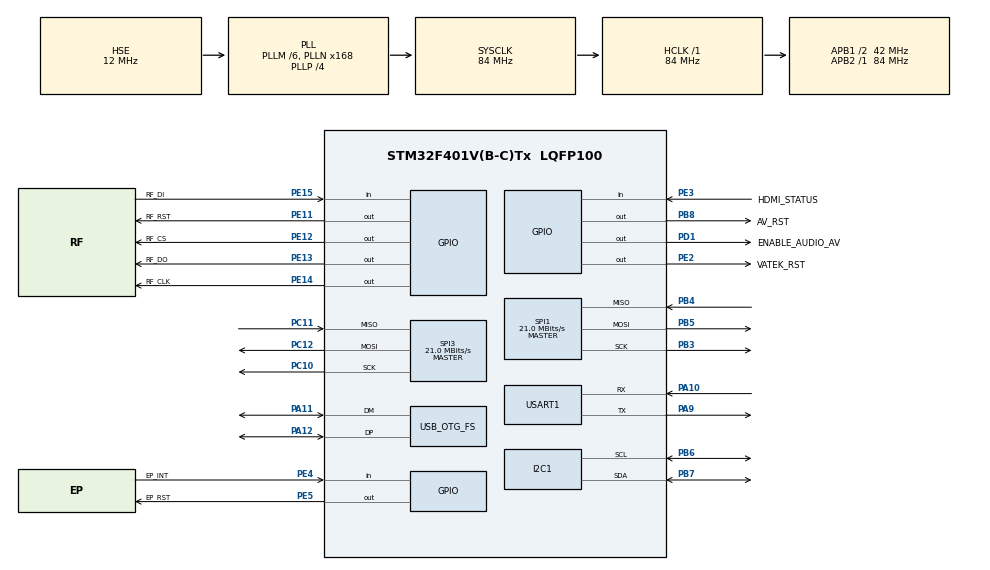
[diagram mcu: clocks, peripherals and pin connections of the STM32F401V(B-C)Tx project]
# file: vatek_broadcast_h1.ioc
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I2C1.I2C_Mode=I2C_Fast
Mcu.Family=STM32F4
Mcu.Name=STM32F401V(B-C)Tx
Mcu.Package=LQFP100
NVIC.OTG_FS_IRQn=true\:0\:0\:false\:false\:true\:false\:true
NVIC.PriorityGroup=NVIC_PRIORITYGROUP_4
NVIC.USART1_IRQn=true\:0\:0\:false\:false\:true\:true\:true
PA10.Mode=Asynchronous
PA10.Signal=USART1_RX
PA11.Mode=Device_Only
PA11.Signal=USB_OTG_FS_DM
PA12.Mode=Device_Only
PA12.Signal=USB_OTG_FS_DP
PA13.Mode=Serial_Wire
PA13.Signal=SYS_JTMS-SWDIO
PA14.Mode=Serial_Wire
PA14.Signal=SYS_JTCK-SWCLK
PA9.Mode=Asynchronous
PA9.Signal=USART1_TX
PB3.Mode=Full_Duplex_Master
PB3.Signal=SPI1_SCK
PB4.Mode=Full_Duplex_Master
PB4.Signal=SPI1_MISO
PB5.Mode=Full_Duplex_Master
PB5.Signal=SPI1_MOSI
PB6.Mode=I2C
PB6.Signal=I2C1_SCL
PB7.Mode=I2C
PB7.Signal=I2C1_SDA
PB8.GPIO_Label=AV_RST
PB8.Signal=GPIO_Output
PC10.Mode=Full_Duplex_Master
PC10.Signal=SPI3_SCK
PC11.Mode=Full_Duplex_Master
PC11.Signal=SPI3_MISO
PC12.Mode=Full_Duplex_Master
PC12.Signal=SPI3_MOSI
PC14-OSC32_IN.Mode=LSE-External-Oscillator
PC14-OSC32_IN.Signal=RCC_OSC32_IN
PC15-OSC32_OUT.Mode=LSE-External-Oscillator
PC15-OSC32_OUT.Signal=RCC_OSC32_OUT
PD1.GPIO_Label=ENABLE_AUDIO_AV
PD1.Signal=GPIO_Output
PE11.GPIO_Label=RF_RST
PE11.Signal=GPIO_Output
PE12.GPIO_Label=RF_CS
PE12.Signal=GPIO_Output
PE13.GPIO_Label=RF_DO
PE13.Signal=GPIO_Output
PE14.GPIO_Label=RF_CLK
PE14.Signal=GPIO_Output
PE15.GPIO_Label=RF_DI
PE15.Signal=GPIO_Input
PE2.GPIO_Label=VATEK_RST
PE2.Signal=GPIO_Output
PE3.GPIO_Label=HDMI_STATUS
PE3.Signal=GPIO_Input
PE4.GPIO_Label=EP_INT
PE4.Signal=GPIO_Input
PE5.GPIO_Label=EP_RST
PE5.Signal=GPIO_Output
PH0\ -\ OSC_IN.Mode=HSE-External-Oscillator
PH0\ -\ OSC_IN.Signal=RCC_OSC_IN
PH1\ -\ OSC_OUT.Mode=HSE-External-Oscillator
PH1\ -\ OSC_OUT.Signal=RCC_OSC_OUT
ProjectManager.HeapSize=0x4000
ProjectManager.StackSize=0x800
ProjectManager.TargetToolchain=MDK-ARM V5.27
RCC.48MHZClocksFreq_Value=48000000
RCC.AHBFreq_Value=84000000
RCC.APB1CLKDivider=RCC_HCLK_DIV2
RCC.APB1Freq_Value=42000000
RCC.APB1TimFreq_Value=84000000
RCC.APB2Freq_Value=84000000
RCC.APB2TimFreq_Value=84000000
RCC.CortexFreq_Value=84000000
RCC.HCLKFreq_Value=84000000
RCC.HSE_VALUE=12000000
RCC.HSI_VALUE=16000000
RCC.PLLM=6
RCC.PLLN=168
RCC.PLLP=RCC_PLLP_DIV4
RCC.PLLQ=7
RCC.SYSCLKFreq_VALUE=84000000
RCC.SYSCLKSource=RCC_SYSCLKSOURCE_PLLCLK
RCC.VCOOutputFreq_Value=336000000
SPI1.BaudRatePrescaler=SPI_BAUDRATEPRESCALER_4
SPI1.CalculateBaudRate=21.0 MBits/s
SPI1.Direction=SPI_DIRECTION_2LINES
SPI1.Mode=SPI_MODE_MASTER
SPI1.VirtualType=VM_MASTER
SPI3.BaudRatePrescaler=SPI_BAUDRATEPRESCALER_2
SPI3.CalculateBaudRate=21.0 MBits/s
SPI3.Direction=SPI_DIRECTION_2LINES
SPI3.Mode=SPI_MODE_MASTER
SPI3.VirtualType=VM_MASTER
USART1.VirtualMode=VM_ASYNC
USB_DEVICE.CLASS_NAME_FS=CUSTOM_HID
USB_DEVICE.USBD_CUSTOMHID_OUTREPORT_BUF_SIZE=64
USB_DEVICE.USBD_CUSTOM_HID_REPORT_DESC_SIZE=33
USB_DEVICE.USBD_MAX_STR_DESC_SIZ=64
USB_DEVICE.VirtualMode=CustomHid
USB_DEVICE.VirtualModeFS=Custom_Hid_FS
USB_OTG_FS.VirtualMode=Device_Only
VP_RTC_VS_RTC_Activate.Mode=RTC_Enabled
VP_USB_DEVICE_VS_USB_DEVICE_CUSTOM_HID_FS.Mode=CUSTOM_HID_FS
board=custom

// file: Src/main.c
/* USER CODE BEGIN Header */
/**
  ******************************************************************************
  * @file           : main.c
  * @brief          : Main program body
  ******************************************************************************
  * @attention
  *
  * <h2><center>&copy; Copyright (c) 2021 STMicroelectronics.
  * All rights reserved.</center></h2>
  *
  * This software component is licensed by ST under Ultimate Liberty license
  * SLA0044, the "License"; You may not use this file except in compliance with
  * the License. You may obtain a copy of the License at:
  *                             www.st.com/SLA0044
  *
  ******************************************************************************
  */
/* USER CODE END Header */

#include "main.h"
#include "i2c.h"
#include "rtc.h"
#include "spi.h"
#include "usart.h"
#include "usb_device.h"
#include "gpio.h"

/* USER CODE BEGIN Includes */
#include "vatek_sample_broadcast_via_h1.h"
/* USER CODE END Includes */

void SystemClock_Config(void);

int main(void)
{

  /* MCU Configuration--------------------------------------------------------*/

  /* Reset of all peripherals, Initializes the Flash interface and the Systick. */
  HAL_Init();

  /* Configure the system clock */
  SystemClock_Config();

  /* Initialize all configured peripherals */
  MX_GPIO_Init();
  MX_I2C1_Init();
  MX_RTC_Init();
  MX_SPI1_Init();
  MX_SPI3_Init();
  MX_USART1_UART_Init();
  MX_USB_DEVICE_Init();
  /* USER CODE BEGIN 2 */
  sample_bc_init(&hi2c1, &hi2c1, &hi2c1);
  /* USER CODE END 2 */

  /* Infinite loop */
  while (1)
  {
    sample_bc_polling();
  }
}

void SystemClock_Config(void)
{
  RCC_OscInitTypeDef RCC_OscInitStruct = {0};
  RCC_ClkInitTypeDef RCC_ClkInitStruct = {0};
  RCC_PeriphCLKInitTypeDef PeriphClkInitStruct = {0};

  /** Configure the main internal regulator output voltage
  */
  __HAL_RCC_PWR_CLK_ENABLE();
  __HAL_PWR_VOLTAGESCALING_CONFIG(PWR_REGULATOR_VOLTAGE_SCALE2);
  /** Initializes the CPU, AHB and APB busses clocks
  */
  RCC_OscInitStruct.OscillatorType = RCC_OSCILLATORTYPE_LSI|RCC_OSCILLATORTYPE_HSE;
  RCC_OscInitStruct.HSEState = RCC_HSE_ON;
  RCC_OscInitStruct.LSIState = RCC_LSI_ON;
  RCC_OscInitStruct.PLL.PLLState = RCC_PLL_ON;
  RCC_OscInitStruct.PLL.PLLSource = RCC_PLLSOURCE_HSE;
  RCC_OscInitStruct.PLL.PLLM = 6;
  RCC_OscInitStruct.PLL.PLLN = 168;
  RCC_OscInitStruct.PLL.PLLP = RCC_PLLP_DIV4;
  RCC_OscInitStruct.PLL.PLLQ = 7;
  if (HAL_RCC_OscConfig(&RCC_OscInitStruct) != HAL_OK)
  {
    Error_Handler();
  }
  /** Initializes the CPU, AHB and APB busses clocks
  */
  RCC_ClkInitStruct.ClockType = RCC_CLOCKTYPE_HCLK|RCC_CLOCKTYPE_SYSCLK
                              |RCC_CLOCKTYPE_PCLK1|RCC_CLOCKTYPE_PCLK2;
  RCC_ClkInitStruct.SYSCLKSource = RCC_SYSCLKSOURCE_PLLCLK;
  RCC_ClkInitStruct.AHBCLKDivider = RCC_SYSCLK_DIV1;
  RCC_ClkInitStruct.APB1CLKDivider = RCC_HCLK_DIV2;
  RCC_ClkInitStruct.APB2CLKDivider = RCC_HCLK_DIV1;

  if (HAL_RCC_ClockConfig(&RCC_ClkInitStruct, FLASH_LATENCY_2) != HAL_OK)
  {
    Error_Handler();
  }
  PeriphClkInitStruct.PeriphClockSelection = RCC_PERIPHCLK_RTC;
  PeriphClkInitStruct.RTCClockSelection = RCC_RTCCLKSOURCE_LSI;
  if (HAL_RCCEx_PeriphCLKConfig(&PeriphClkInitStruct) != HAL_OK)
  {
    Error_Handler();
  }
}

void Error_Handler(void)
{
}

/************************ (C) COPYRIGHT STMicroelectronics *****END OF FILE****/
